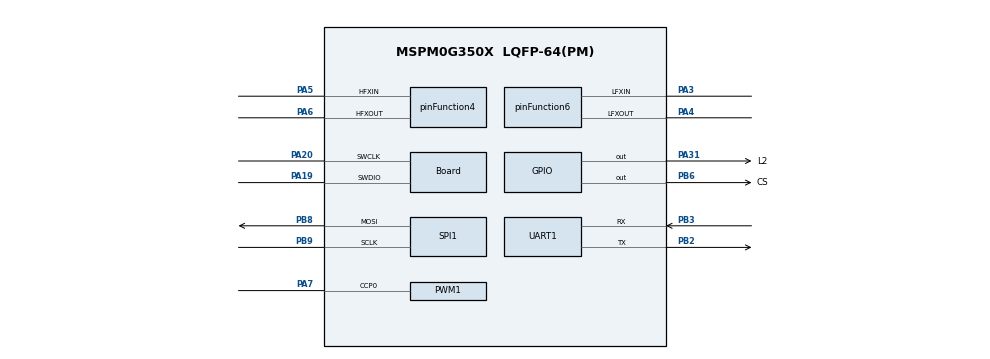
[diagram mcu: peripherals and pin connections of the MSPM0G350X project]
/**
 * @cliArgs --device "MSPM0G350X" --package "LQFP-64(PM)" --part "Default" --product "mspm0_sdk@1.20.01.06"
 * @versions {"tool":"1.18.1+3343"}
 */

/**
 * Import the modules used in this configuration.
 */
const Board         = scripting.addModule("/ti/driverlib/Board");
const GPIO          = scripting.addModule("/ti/driverlib/GPIO", {}, false);
const GPIO1         = GPIO.addInstance();
const GPIO2         = GPIO.addInstance();
const PWM           = scripting.addModule("/ti/driverlib/PWM", {}, false);
const PWM1          = PWM.addInstance();
const SPI           = scripting.addModule("/ti/driverlib/SPI", {}, false);
const SPI1          = SPI.addInstance();
const SYSCTL        = scripting.addModule("/ti/driverlib/SYSCTL");
const UART          = scripting.addModule("/ti/driverlib/UART", {}, false);
const UART1         = UART.addInstance();
const ProjectConfig = scripting.addModule("/ti/project_config/ProjectConfig");

/**
 * Write custom configuration values to the imported modules.
 */
const divider2       = system.clockTree["HFCLK4MFPCLKDIV"];
divider2.divideValue = 10;

const divider9       = system.clockTree["UDIV"];
divider9.divideValue = 2;

const gate7  = system.clockTree["MFCLKGATE"];
gate7.enable = true;

const gate8  = system.clockTree["MFPCLKGATE"];
gate8.enable = true;

const multiplier2         = system.clockTree["PLL_QDIV"];
multiplier2.multiplyValue = 4;

const mux4       = system.clockTree["EXHFMUX"];
mux4.inputSelect = "EXHFMUX_XTAL";

const mux5       = system.clockTree["EXLFMUX"];
mux5.inputSelect = "EXLFMUX_XTAL";

const mux8       = system.clockTree["HSCLKMUX"];
mux8.inputSelect = "HSCLKMUX_SYSPLL0";

const mux10       = system.clockTree["MFPCLKMUX"];
mux10.inputSelect = "MFPCLKMUX_HFCLK";

const mux12       = system.clockTree["SYSPLLMUX"];
mux12.inputSelect = "zSYSPLLMUX_HFCLK";

const pinFunction4                        = system.clockTree["HFXT"];
pinFunction4.enable                       = true;
pinFunction4.inputFreq                    = 40;
pinFunction4.peripheral.hfxInPin.$assign  = "PA5";
pinFunction4.peripheral.hfxOutPin.$assign = "PA6";

const pinFunction6                        = system.clockTree["LFXT"];
pinFunction6.enable                       = true;
pinFunction6.inputFreq                    = 32.768;
pinFunction6.peripheral.lfxInPin.$assign  = "PA3";
pinFunction6.peripheral.lfxOutPin.$assign = "PA4";

Board.peripheral.$assign          = "DEBUGSS";
Board.peripheral.swclkPin.$assign = "PA20";
Board.peripheral.swdioPin.$assign = "PA19";

GPIO1.$name                          = "LED";
GPIO1.associatedPins.create(2);
GPIO1.associatedPins[0].initialValue = "SET";
GPIO1.associatedPins[0].$name        = "L1";
GPIO1.associatedPins[0].assignedPort = "PORTA";
GPIO1.associatedPins[0].assignedPin  = "28";
GPIO1.associatedPins[1].$name        = "L2";
GPIO1.associatedPins[1].pin.$assign  = "PA31";

GPIO2.$name                          = "OLED";
GPIO2.associatedPins.create(3);
GPIO2.associatedPins[0].$name        = "DC";
GPIO2.associatedPins[0].assignedPort = "PORTB";
GPIO2.associatedPins[0].assignedPin  = "7";
GPIO2.associatedPins[1].$name        = "RES";
GPIO2.associatedPins[1].assignedPort = "PORTB";
GPIO2.associatedPins[1].assignedPin  = "1";
GPIO2.associatedPins[2].$name        = "CS";
GPIO2.associatedPins[2].assignedPin  = "6";
GPIO2.associatedPins[2].pin.$assign  = "PB6";

PWM1.$name                              = "PWM_SG90";
PWM1.clockDivider                       = 8;
PWM1.timerStartTimer                    = true;
PWM1.ccIndex                            = [0];
PWM1.timerCount                         = 400;
PWM1.clockPrescale                      = 200;
PWM1.peripheral.$assign                 = "TIMG8";
PWM1.peripheral.ccp0Pin.$assign         = "PA7";
PWM1.PWM_CHANNEL_0.$name                = "ti_driverlib_pwm_PWMTimerCC0";
PWM1.PWM_CHANNEL_0.invert               = true;
PWM1.ccp0PinConfig.$name                = "ti_driverlib_gpio_GPIOPinGeneric0";
PWM1.ccp0PinConfig.direction            = scripting.forceWrite("OUTPUT");
PWM1.ccp0PinConfig.hideOutputInversion  = scripting.forceWrite(false);
PWM1.ccp0PinConfig.onlyInternalResistor = scripting.forceWrite(false);
PWM1.ccp0PinConfig.passedPeripheralType = scripting.forceWrite("Digital");

SPI1.$name                      = "SPI_0";
SPI1.chipSelect                 = [];
SPI1.frameFormat                = "MOTO3";
SPI1.direction                  = "PICO";
SPI1.peripheral.$assign         = "SPI1";
SPI1.peripheral.sclkPin.$assign = "PB9";
SPI1.peripheral.mosiPin.$assign = "PB8";
SPI1.sclkPinConfig.$name        = "ti_driverlib_gpio_GPIOPinGeneric2";
SPI1.mosiPinConfig.$name        = "ti_driverlib_gpio_GPIOPinGeneric3";

SYSCTL.MFCLKEn     = true;
SYSCTL.MFPCLKEn    = true;
SYSCTL.clockTreeEn = true;

UART1.enabledInterrupts                = ["RX"];
UART1.$name                            = "BlueTooth";
UART1.targetBaudRate                   = 115200;
UART1.peripheral.$assign               = "UART3";
UART1.peripheral.rxPin.$assign         = "PB3";
UART1.peripheral.txPin.$assign         = "PB2";
UART1.txPinConfig.$name                = "ti_driverlib_gpio_GPIOPinGeneric6";
UART1.txPinConfig.direction            = scripting.forceWrite("OUTPUT");
UART1.txPinConfig.hideOutputInversion  = scripting.forceWrite(false);
UART1.txPinConfig.onlyInternalResistor = scripting.forceWrite(false);
UART1.txPinConfig.passedPeripheralType = scripting.forceWrite("Digital");
UART1.rxPinConfig.$name                = "ti_driverlib_gpio_GPIOPinGeneric7";
UART1.rxPinConfig.hideOutputInversion  = scripting.forceWrite(false);
UART1.rxPinConfig.onlyInternalResistor = scripting.forceWrite(false);
UART1.rxPinConfig.passedPeripheralType = scripting.forceWrite("Digital");

ProjectConfig.deviceSpin = "MSPM0G3507";

/**
 * Pinmux solution for unlocked pins/peripherals. This ensures that minor changes to the automatic solver in a future
 * version of the tool will not impact the pinmux you originally saw.  These lines can be completely deleted in order to
 * re-solve from scratch.
 */
pinFunction4.peripheral.$suggestSolution     = "SYSCTL";
pinFunction6.peripheral.$suggestSolution     = "SYSCTL";
GPIO1.associatedPins[0].pin.$suggestSolution = "PA28";
GPIO2.associatedPins[0].pin.$suggestSolution = "PB7";
GPIO2.associatedPins[1].pin.$suggestSolution = "PB1";
